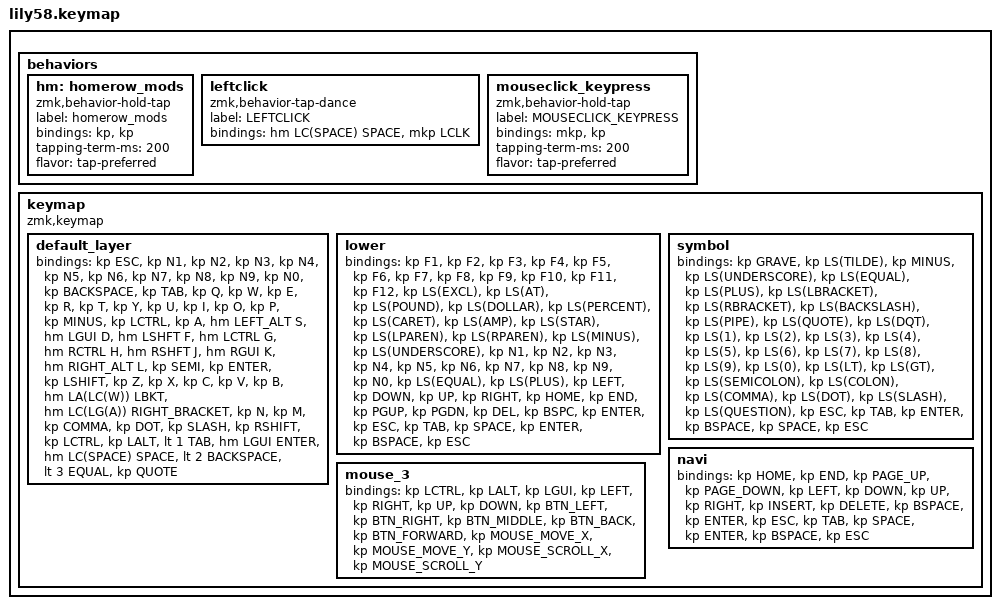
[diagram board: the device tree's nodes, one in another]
/*
 * Copyright (c) 2020 The ZMK Contributors
 * SPDX-License-Identifier: MIT
 */

#define BASE 0
#define LOWER 1
#define MOUSE_KEYS 2
#define MOUSE_TP 3
#define MOUSE_TP_SET 4

/* -----------------------------------------------------------------
 * Optional feature toggles – you can leave them as‑is or adjust.
 * ----------------------------------------------------------------- */
#define HAS_MOUSE_KEYS
#define HAS_MOUSE_TP

#include <dt-bindings/zmk/mouse.h>
#include <behaviors/mouse_keys.dtsi>

/* -------------------------------------------------------------
 *  Behaviors (hold‑tap, tap‑dance, etc.)
 * ------------------------------------------------------------- */
#include <behaviors.dtsi>
#include <dt-bindings/zmk/bt.h>
#include <dt-bindings/zmk/keys.h>
#include <dt-bindings/zmk/pointing.h>

{
    behaviors {
        hm: homerow_mods {
            compatible = "zmk,behavior-hold-tap";
            label = "homerow_mods";
            bindings = <&kp>, <&kp>;
            #binding-cells = <2>;
            tapping-term-ms = <200>;
            flavor = "tap-preferred";
        };

        leftclick: leftclick {
            compatible = "zmk,behavior-tap-dance";
            label = "LEFTCLICK";
            #binding-cells = <0>;
            bindings = <&hm LC(SPACE) SPACE>, <&mkp LCLK>;
        };

        mouseclick_keypress: mouseclick_keypress {
            compatible = "zmk,behavior-hold-tap";
            label = "MOUSECLICK_KEYPRESS";
            bindings = <&mkp>, <&kp>;
            #binding-cells = <2>;
            tapping-term-ms = <200>;
            flavor = "tap-preferred";
        };
    };

    keymap {
        compatible = "zmk,keymap";

        /* -----------------------------------------------------------------
         *  BASE LAYER – standard QWERTY layout (the row with Z X C V B
         *  is now explicitly present, with correct Shift‑behaviour).
         * ----------------------------------------------------------------- */
        default_layer {
            /* -----------------------------------------------------------------
            *  BASE LAYER – QWERTY (the row with Z X C V B is now fixed)
            * ----------------------------------------------------------------- */
            bindings = <
                /* Row 0 – top (ESC…) */
                &kp ESC      &kp N1   &kp N2   &kp N3   &kp N4   &kp N5   &kp N6   &kp N7   &kp N8   &kp N9   &kp N0   &kp BACKSPACE

                /* Row 1 – Q‑row */
                &kp TAB      &kp Q    &kp W    &kp E    &kp R    &kp T    &kp Y    &kp U    &kp I    &kp O    &kp P    &kp MINUS

                /* Row 2 – A‑row */
                &kp LCTRL    &kp A    &hm LEFT_ALT S   &hm LGUI D      &hm LSHFT F   &hm LCTRL G
                &hm RCTRL H  &hm RSHFT J   &hm RGUI K   &hm RIGHT_ALT L   &kp SEMI   &kp ENTER

                /* Row 3 – Z‑row (the problematic one) */
                &kp LSHIFT   &kp Z    &kp X    &kp C    &kp V    &kp B
                &hm LA(LC(W)) LBKT     &hm LC(LG(A)) RIGHT_BRACKET
                &kp N        &kp M    &kp COMMA   &kp DOT   &kp SLASH   &kp RSHIFT

                /* Bottom row – modifiers / layer‑tap keys */
                &kp LCTRL    &kp LALT   &lt 1 TAB          /* LT‑1 : hold → LOWER layer, tap → TAB */
                &hm LGUI ENTER                     /* your custom LGUI‑ENTER behaviour */
                &hm LC(SPACE) SPACE                /* space with homerow‑mods */
                &lt 2 BACKSPACE                    /* LT‑2 : hold → RAISE layer, tap → Backspace */
                &lt 3 EQUAL                        /* LT‑3 : hold → ??? layer, tap → = */
                &kp QUOTE
            >;
        };


        /* -----------------------------------------------------------------
         *  LOWER LAYER – activated with the `LT(1, …)` key in the bottom row
         * ----------------------------------------------------------------- */
        lower {
            bindings = <
                /* Top row – function keys + navigation */
                &kp F1   &kp F2   &kp F3   &kp F4   &kp F5   &kp F6
                &kp F7   &kp F8   &kp F9   &kp F10  &kp F11  &kp F12

                /* Second row – symbols */
                &kp LS(EXCL)   &kp LS(AT)   &kp LS(POUND)   &kp LS(DOLLAR)  &kp LS(PERCENT)  &kp LS(CARET)
                &kp LS(AMP)    &kp LS(STAR) &kp LS(LPAREN)  &kp LS(RPAREN)  &kp LS(MINUS)    &kp LS(UNDERSCORE)

                /* Third row – numbers / shortcuts */
                &kp N1 &kp N2 &kp N3 &kp N4 &kp N5 &kp N6
                &kp N7 &kp N8 &kp N9 &kp N0 &kp LS(EQUAL) &kp LS(PLUS)

                /* Fourth row – navigation / editing */
                &kp LEFT &kp DOWN &kp UP &kp RIGHT
                &kp HOME &kp END &kp PGUP &kp PGDN
                &kp DEL &kp BSPC &kp ENTER

                /* Bottom row – layer keys */
                &kp ESC   &kp TAB   &kp SPACE   &kp ENTER   &kp BSPACE   &kp ESC
            >;
        };

        /* -----------------------------------------------------------------
         *  SYMBOL LAYER – accessed with a dedicated layer key if you want one.
         *  (You can delete the whole section if you never use it.)
         * ----------------------------------------------------------------- */
        symbol {
            bindings = <
                &kp GRAVE   &kp LS(TILDE)   &kp MINUS   &kp LS(UNDERSCORE)   &kp LS(EQUAL)   &kp LS(PLUS)
                &kp LS(LBRACKET)   &kp LS(RBRACKET)   &kp LS(BACKSLASH)   &kp LS(PIPE)   &kp LS(QUOTE)   &kp LS(DQT)

                &kp LS(1)   &kp LS(2)   &kp LS(3)   &kp LS(4)   &kp LS(5)   &kp LS(6)
                &kp LS(7)   &kp LS(8)   &kp LS(9)   &kp LS(0)   &kp LS(LT)   &kp LS(GT)

                &kp LS(SEMICOLON)   &kp LS(COLON)   &kp LS(COMMA)   &kp LS(DOT)
                &kp LS(SLASH)   &kp LS(QUESTION)

                &kp ESC   &kp TAB   &kp ENTER   &kp BSPACE   &kp SPACE   &kp ESC
            >;
        };

        /* -----------------------------------------------------------------
         *  NAVIGATION LAYER – optional, activated with a dedicated key.
         * ----------------------------------------------------------------- */
        navi {
            bindings = <
                &kp HOME   &kp END   &kp PAGE_UP   &kp PAGE_DOWN
                &kp LEFT   &kp DOWN   &kp UP   &kp RIGHT
                &kp INSERT   &kp DELETE   &kp BSPACE   &kp ENTER
                &kp ESC   &kp TAB   &kp SPACE   &kp ENTER   &kp BSPACE   &kp ESC
            >;
        };

        /* -----------------------------------------------------------------
         *  MOUSE LAYER – you already have mouse‑pointing enabled.
         * ----------------------------------------------------------------- */
        mouse_3 {
            bindings = <
                &kp LCTRL   &kp LALT   &kp LGUI   &kp LEFT   &kp RIGHT   &kp UP
                &kp DOWN   &kp BTN_LEFT   &kp BTN_RIGHT   &kp BTN_MIDDLE   &kp BTN_BACK   &kp BTN_FORWARD
                &kp MOUSE_MOVE_X  &kp MOUSE_MOVE_Y  &kp MOUSE_SCROLL_X  &kp MOUSE_SCROLL_Y
            >;
        };
    };
};
